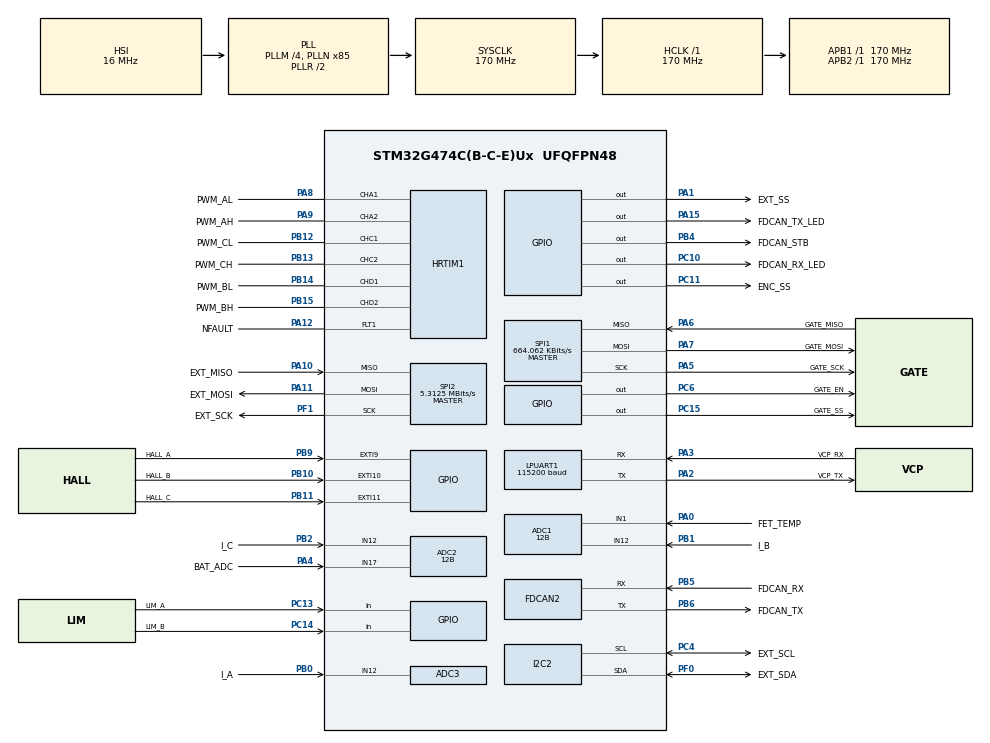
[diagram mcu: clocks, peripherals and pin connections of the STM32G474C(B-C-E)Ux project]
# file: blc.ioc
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ADC1.Channel-2\#ChannelRegularConversion=ADC_CHANNEL_1
ADC1.Channel-3\#ChannelRegularConversion=ADC_CHANNEL_TEMPSENSOR_ADC1
ADC1.Channel-4\#ChannelRegularConversion=ADC_CHANNEL_VREFINT
ADC1.ClockPrescaler=ADC_CLOCK_SYNC_PCLK_DIV4
ADC1.ContinuousConvMode=ENABLE
ADC1.DMAContinuousRequests=ENABLE
ADC1.DataAlign=ADC_DATAALIGN_RIGHT
ADC1.EnableInjectedConversion=ENABLE
ADC1.EnableRegularConversion=ENABLE
ADC1.ExternalTrigConv=ADC_SOFTWARE_START
ADC1.ExternalTrigInjecConv=ADC_EXTERNALTRIGINJEC_HRTIM_TRG5
ADC1.InjNumberOfConversion=1
ADC1.InjectedChannel-1\#ChannelInjectedConversion=ADC_CHANNEL_12
ADC1.InjectedOffset-1\#ChannelInjectedConversion=0
ADC1.InjectedOffsetNumber-1\#ChannelInjectedConversion=ADC_OFFSET_1
ADC1.InjectedOffsetSaturation-1\#ChannelInjectedConversion=DISABLE
ADC1.InjectedOffsetSign-1\#ChannelInjectedConversion=ADC_OFFSET_SIGN_NEGATIVE
ADC1.InjectedRank-1\#ChannelInjectedConversion=1
ADC1.InjectedSamplingTime-1\#ChannelInjectedConversion=ADC_SAMPLETIME_24CYCLES_5
ADC1.NbrOfConversion=3
ADC1.NbrOfConversionFlag=1
ADC1.OffsetNumber-2\#ChannelRegularConversion=ADC_OFFSET_NONE
ADC1.OffsetNumber-3\#ChannelRegularConversion=ADC_OFFSET_NONE
ADC1.OffsetNumber-4\#ChannelRegularConversion=ADC_OFFSET_NONE
ADC1.Overrun=ADC_OVR_DATA_OVERWRITTEN
ADC1.OversamplingMode=ENABLE
ADC1.OversamplingStopReset=ADC_REGOVERSAMPLING_CONTINUED_MODE
ADC1.Rank-2\#ChannelRegularConversion=1
ADC1.Rank-3\#ChannelRegularConversion=2
ADC1.Rank-4\#ChannelRegularConversion=3
ADC1.Ratio=ADC_OVERSAMPLING_RATIO_256
ADC1.Resolution=ADC_RESOLUTION_12B
ADC1.RightBitShift=ADC_RIGHTBITSHIFT_4
ADC1.SamplingTime-2\#ChannelRegularConversion=ADC_SAMPLETIME_47CYCLES_5
ADC1.SamplingTime-3\#ChannelRegularConversion=ADC_SAMPLETIME_247CYCLES_5
ADC1.SamplingTime-4\#ChannelRegularConversion=ADC_SAMPLETIME_247CYCLES_5
ADC1.ScanConvMode=ADC_SCAN_ENABLE
ADC1.TriggeredMode=ADC_TRIGGEREDMODE_SINGLE_TRIGGER
ADC1.master=1
ADC2.Channel-0\#ChannelRegularConversion=ADC_CHANNEL_17
ADC2.ClockPrescaler=ADC_CLOCK_SYNC_PCLK_DIV4
ADC2.ContinuousConvMode=ENABLE
ADC2.DMAContinuousRequests=ENABLE
ADC2.DataAlign=ADC_DATAALIGN_RIGHT
ADC2.EnableInjectedConversion=ENABLE
ADC2.EnableRegularConversion=ENABLE
ADC2.ExternalTrigConv=ADC_SOFTWARE_START
ADC2.ExternalTrigInjecConv=ADC_EXTERNALTRIGINJEC_HRTIM_TRG5
ADC2.InjNumberOfConversion=1
ADC2.InjectedChannel-1\#ChannelInjectedConversion=ADC_CHANNEL_12
ADC2.InjectedOffset-1\#ChannelInjectedConversion=0
ADC2.InjectedOffsetNumber-1\#ChannelInjectedConversion=ADC_OFFSET_1
ADC2.InjectedOffsetSaturation-1\#ChannelInjectedConversion=DISABLE
ADC2.InjectedOffsetSign-1\#ChannelInjectedConversion=ADC_OFFSET_SIGN_NEGATIVE
ADC2.InjectedRank-1\#ChannelInjectedConversion=1
ADC2.InjectedSamplingTime-1\#ChannelInjectedConversion=ADC_SAMPLETIME_24CYCLES_5
ADC2.NbrOfConversion=1
ADC2.NbrOfConversionFlag=1
ADC2.OffsetNumber-0\#ChannelRegularConversion=ADC_OFFSET_NONE
ADC2.Overrun=ADC_OVR_DATA_OVERWRITTEN
ADC2.OversamplingMode=ENABLE
ADC2.OversamplingStopReset=ADC_REGOVERSAMPLING_CONTINUED_MODE
ADC2.Rank-0\#ChannelRegularConversion=1
ADC2.Rank1_Channel=ADC_CHANNEL_12
ADC2.Ratio=ADC_OVERSAMPLING_RATIO_8
ADC2.Resolution=ADC_RESOLUTION_12B
ADC2.RightBitShift=ADC_RIGHTBITSHIFT_3
ADC2.SamplingTime-0\#ChannelRegularConversion=ADC_SAMPLETIME_247CYCLES_5
ADC2.TriggeredMode=ADC_TRIGGEREDMODE_SINGLE_TRIGGER
ADC3.ClockPrescaler=ADC_CLOCK_SYNC_PCLK_DIV4
ADC3.DataAlign=ADC_DATAALIGN_RIGHT
ADC3.EnableInjectedConversion=ENABLE
ADC3.EnableRegularConversion=DISABLE
ADC3.ExternalTrigInjecConv=ADC_EXTERNALTRIGINJEC_HRTIM_TRG5
ADC3.InjNumberOfConversion=1
ADC3.InjectedChannel-1\#ChannelInjectedConversion=ADC_CHANNEL_12
ADC3.InjectedOffset-1\#ChannelInjectedConversion=0
ADC3.InjectedOffsetNumber-1\#ChannelInjectedConversion=ADC_OFFSET_1
ADC3.InjectedOffsetSaturation-1\#ChannelInjectedConversion=DISABLE
ADC3.InjectedOffsetSign-1\#ChannelInjectedConversion=ADC_OFFSET_SIGN_NEGATIVE
ADC3.InjectedRank-1\#ChannelInjectedConversion=1
ADC3.InjectedSamplingTime-1\#ChannelInjectedConversion=ADC_SAMPLETIME_24CYCLES_5
ADC3.Rank1_Channel=ADC_CHANNEL_12
ADC3.Resolution=ADC_RESOLUTION_12B
ADC3.master=1
Dma.ADC1.0.Direction=DMA_PERIPH_TO_MEMORY
Dma.ADC1.0.EventEnable=DISABLE
Dma.ADC1.0.Instance=DMA1_Channel1
Dma.ADC1.0.MemDataAlignment=DMA_MDATAALIGN_HALFWORD
Dma.ADC1.0.MemInc=DMA_MINC_ENABLE
Dma.ADC1.0.Mode=DMA_CIRCULAR
Dma.ADC1.0.PeriphDataAlignment=DMA_PDATAALIGN_HALFWORD
Dma.ADC1.0.PeriphInc=DMA_PINC_DISABLE
Dma.ADC1.0.Polarity=HAL_DMAMUX_REQ_GEN_RISING
Dma.ADC1.0.Priority=DMA_PRIORITY_LOW
Dma.ADC1.0.RequestNumber=1
Dma.ADC1.0.SignalID=NONE
Dma.ADC1.0.SyncEnable=DISABLE
Dma.ADC1.0.SyncPolarity=HAL_DMAMUX_SYNC_NO_EVENT
Dma.ADC1.0.SyncRequestNumber=1
Dma.ADC1.0.SyncSignalID=NONE
Dma.ADC2.1.Direction=DMA_PERIPH_TO_MEMORY
Dma.ADC2.1.EventEnable=DISABLE
Dma.ADC2.1.Instance=DMA1_Channel2
Dma.ADC2.1.MemDataAlignment=DMA_MDATAALIGN_HALFWORD
Dma.ADC2.1.MemInc=DMA_MINC_ENABLE
Dma.ADC2.1.Mode=DMA_CIRCULAR
Dma.ADC2.1.PeriphDataAlignment=DMA_PDATAALIGN_HALFWORD
Dma.ADC2.1.PeriphInc=DMA_PINC_DISABLE
Dma.ADC2.1.Polarity=HAL_DMAMUX_REQ_GEN_RISING
Dma.ADC2.1.Priority=DMA_PRIORITY_LOW
Dma.ADC2.1.RequestNumber=1
Dma.ADC2.1.SignalID=NONE
Dma.ADC2.1.SyncEnable=DISABLE
Dma.ADC2.1.SyncPolarity=HAL_DMAMUX_SYNC_NO_EVENT
Dma.ADC2.1.SyncRequestNumber=1
Dma.ADC2.1.SyncSignalID=NONE
Dma.LPUART1_TX.4.Direction=DMA_MEMORY_TO_PERIPH
Dma.LPUART1_TX.4.EventEnable=DISABLE
Dma.LPUART1_TX.4.Instance=DMA1_Channel5
Dma.LPUART1_TX.4.MemDataAlignment=DMA_MDATAALIGN_BYTE
Dma.LPUART1_TX.4.MemInc=DMA_MINC_ENABLE
Dma.LPUART1_TX.4.Mode=DMA_NORMAL
Dma.LPUART1_TX.4.PeriphDataAlignment=DMA_PDATAALIGN_BYTE
Dma.LPUART1_TX.4.PeriphInc=DMA_PINC_DISABLE
Dma.LPUART1_TX.4.Polarity=HAL_DMAMUX_REQ_GEN_RISING
Dma.LPUART1_TX.4.Priority=DMA_PRIORITY_LOW
Dma.LPUART1_TX.4.RequestNumber=1
Dma.LPUART1_TX.4.SignalID=NONE
Dma.LPUART1_TX.4.SyncEnable=DISABLE
Dma.LPUART1_TX.4.SyncPolarity=HAL_DMAMUX_SYNC_NO_EVENT
Dma.LPUART1_TX.4.SyncRequestNumber=1
Dma.LPUART1_TX.4.SyncSignalID=NONE
Dma.Request0=ADC1
Dma.Request1=ADC2
Dma.Request2=SPI2_RX
Dma.Request3=SPI2_TX
Dma.Request4=LPUART1_TX
Dma.SPI2_RX.2.Direction=DMA_PERIPH_TO_MEMORY
Dma.SPI2_RX.2.EventEnable=DISABLE
Dma.SPI2_RX.2.Instance=DMA1_Channel3
Dma.SPI2_RX.2.MemDataAlignment=DMA_MDATAALIGN_HALFWORD
Dma.SPI2_RX.2.MemInc=DMA_MINC_ENABLE
Dma.SPI2_RX.2.Mode=DMA_NORMAL
Dma.SPI2_RX.2.PeriphDataAlignment=DMA_PDATAALIGN_HALFWORD
Dma.SPI2_RX.2.PeriphInc=DMA_PINC_DISABLE
Dma.SPI2_RX.2.Polarity=HAL_DMAMUX_REQ_GEN_RISING
Dma.SPI2_RX.2.Priority=DMA_PRIORITY_LOW
Dma.SPI2_RX.2.RequestNumber=1
Dma.SPI2_RX.2.SignalID=NONE
Dma.SPI2_RX.2.SyncEnable=DISABLE
Dma.SPI2_RX.2.SyncPolarity=HAL_DMAMUX_SYNC_NO_EVENT
Dma.SPI2_RX.2.SyncRequestNumber=1
Dma.SPI2_RX.2.SyncSignalID=NONE
Dma.SPI2_TX.3.Direction=DMA_MEMORY_TO_PERIPH
Dma.SPI2_TX.3.EventEnable=DISABLE
Dma.SPI2_TX.3.Instance=DMA1_Channel4
Dma.SPI2_TX.3.MemDataAlignment=DMA_MDATAALIGN_HALFWORD
Dma.SPI2_TX.3.MemInc=DMA_MINC_ENABLE
Dma.SPI2_TX.3.Mode=DMA_NORMAL
Dma.SPI2_TX.3.PeriphDataAlignment=DMA_PDATAALIGN_HALFWORD
Dma.SPI2_TX.3.PeriphInc=DMA_PINC_DISABLE
Dma.SPI2_TX.3.Polarity=HAL_DMAMUX_REQ_GEN_RISING
Dma.SPI2_TX.3.Priority=DMA_PRIORITY_LOW
Dma.SPI2_TX.3.RequestNumber=1
Dma.SPI2_TX.3.SignalID=NONE
Dma.SPI2_TX.3.SyncEnable=DISABLE
Dma.SPI2_TX.3.SyncPolarity=HAL_DMAMUX_SYNC_NO_EVENT
Dma.SPI2_TX.3.SyncRequestNumber=1
Dma.SPI2_TX.3.SyncSignalID=NONE
FDCAN2.AutoRetransmission=ENABLE
FDCAN2.CalculateBaudRateNominal=999999
FDCAN2.CalculateTimeBitNominal=1000
FDCAN2.CalculateTimeQuantumNominal=11.764705882352942
FDCAN2.DataPrescaler=2
FDCAN2.DataSyncJumpWidth=5
FDCAN2.DataTimeSeg1=11
FDCAN2.DataTimeSeg2=5
FDCAN2.ExtFiltersNbr=3
FDCAN2.FrameFormat=FDCAN_FRAME_FD_BRS
FDCAN2.NominalPrescaler=2
FDCAN2.NominalSyncJumpWidth=16
FDCAN2.NominalTimeSeg1=56
FDCAN2.NominalTimeSeg2=28
HRTIM1.ADCTrigger_Id5=HRTIM_ADCTRIGGER_5
HRTIM1.Adrom_TA=HRTIM_TIM_ADROM_VALLEY
HRTIM1.CalibrationRate_nonIT=HRTIM_CALIBRATIONRATE_0
HRTIM1.CompareUnit1-Output_TA1TA2=HRTIM_COMPAREUNIT_1
HRTIM1.CompareUnit1-Output_TC1TC2=HRTIM_COMPAREUNIT_1
HRTIM1.CompareUnit1-Output_TD1TD2=HRTIM_COMPAREUNIT_1
HRTIM1.CompareValue1-Output_TA1TA2=0x84A0
HRTIM1.CompareValue1-Output_TC1TC2=0x84A0
HRTIM1.CompareValue1-Output_TD1TD2=0x84A0
HRTIM1.DeadTimeInsertion-Output_TA1TA2=HRTIM_TIMDEADTIMEINSERTION_ENABLED
HRTIM1.DeadTimeInsertion-Output_TC1TC2=HRTIM_TIMDEADTIMEINSERTION_ENABLED
HRTIM1.DeadTimeInsertion-Output_TD1TD2=HRTIM_TIMDEADTIMEINSERTION_ENABLED
HRTIM1.Deadtimeconfig-Output_TA1TA2=HRTIM_TIMERINDEX_TIMER_A
HRTIM1.Deadtimeconfig-Output_TC1TC2=HRTIM_TIMERINDEX_TIMER_C
HRTIM1.Deadtimeconfig-Output_TD1TD2=HRTIM_TIMERINDEX_TIMER_D
HRTIM1.FallingValue-Output_TA1TA2=204
HRTIM1.FallingValue-Output_TC1TC2=204
HRTIM1.FallingValue-Output_TD1TD2=204
HRTIM1.FaultEnable_Source1-Output_TA1TA2=HRTIM_TIMFAULTENABLE_FAULT1
HRTIM1.FaultEnable_Source1-Output_TC1TC2=HRTIM_TIMFAULTENABLE_FAULT1
HRTIM1.FaultEnable_Source1-Output_TD1TD2=HRTIM_TIMFAULTENABLE_FAULT1
HRTIM1.FaultLevel1-Output_TA1TA2=HRTIM_OUTPUTFAULTLEVEL_INACTIVE
HRTIM1.FaultLevel1-Output_TC1TC2=HRTIM_OUTPUTFAULTLEVEL_INACTIVE
HRTIM1.FaultLevel1-Output_TD1TD2=HRTIM_OUTPUTFAULTLEVEL_INACTIVE
HRTIM1.FaultLevel2-Output_TA1TA2=HRTIM_OUTPUTFAULTLEVEL_INACTIVE
HRTIM1.FaultLevel2-Output_TC1TC2=HRTIM_OUTPUTFAULTLEVEL_INACTIVE
HRTIM1.FaultLevel2-Output_TD1TD2=HRTIM_OUTPUTFAULTLEVEL_INACTIVE
HRTIM1.Filter_FaultLine1=HRTIM_FAULTFILTER_10
HRTIM1.NumberFaultEnable-Output_TA1TA2=1
HRTIM1.NumberFaultEnable-Output_TC1TC2=1
HRTIM1.NumberFaultEnable-Output_TD1TD2=1
HRTIM1.NumberSetSource1-Output_TA1TA2=1
HRTIM1.NumberSetSource1-Output_TC1TC2=1
HRTIM1.NumberSetSource1-Output_TD1TD2=1
HRTIM1.ORingUpdateSource_ADCTrigger5=HRTIM_ADCTRIGGERUPDATE_TIMER_A
HRTIM1.Periode_TA=0x84D0
HRTIM1.Periode_TC=0x84D0
HRTIM1.Periode_TD=0x84D0
HRTIM1.Polarity_FaultLine1=HRTIM_FAULTPOLARITY_LOW
HRTIM1.PreloadEnable-Output_TA1TA2=HRTIM_PRELOAD_ENABLED
HRTIM1.PreloadEnable-Output_TC1TC2=HRTIM_PRELOAD_ENABLED
HRTIM1.PreloadEnable-Output_TD1TD2=HRTIM_PRELOAD_ENABLED
HRTIM1.PrescalerRatio_TA=HRTIM_PRESCALERRATIO_MUL8
HRTIM1.PrescalerRatio_TC=HRTIM_PRESCALERRATIO_MUL8
HRTIM1.PrescalerRatio_TD=HRTIM_PRESCALERRATIO_MUL8
HRTIM1.RepetitionUpdate-Output_TA1TA2=HRTIM_UPDATEONREPETITION_ENABLED
HRTIM1.RepetitionUpdate-Output_TC1TC2=HRTIM_UPDATEONREPETITION_ENABLED
HRTIM1.RepetitionUpdate-Output_TD1TD2=HRTIM_UPDATEONREPETITION_ENABLED
HRTIM1.RisingValue-Output_TA1TA2=204
HRTIM1.RisingValue-Output_TC1TC2=204
HRTIM1.RisingValue-Output_TD1TD2=204
HRTIM1.SetOutput1_Source1-Output_TA1TA2=HRTIM_OUTPUTSET_TIMCMP1
HRTIM1.SetOutput1_Source1-Output_TC1TC2=HRTIM_OUTPUTSET_TIMCMP1
HRTIM1.SetOutput1_Source1-Output_TD1TD2=HRTIM_OUTPUTSET_TIMCMP1
HRTIM1.Source_ADCTrigger5=HRTIM_ADCTRIGGEREVENT579_TIMERA_RESET
HRTIM1.Timeout=10
HRTIM1.UpDownMode-Output_TA1TA2=HRTIM_TIMERUPDOWNMODE_UPDOWN
HRTIM1.UpDownMode-Output_TC1TC2=HRTIM_TIMERUPDOWNMODE_UPDOWN
HRTIM1.UpDownMode-Output_TD1TD2=HRTIM_TIMERUPDOWNMODE_UPDOWN
I2C2.Timing=0x40B285C2
IWDG.Prescaler=IWDG_PRESCALER_32
IWDG.Reload=99
IWDG.Window=4095
LPUART1.BaudRate=115200
Mcu.Family=STM32G4
Mcu.Name=STM32G474C(B-C-E)Ux
Mcu.Package=UFQFPN48
NVIC.ADC1_2_IRQn=true\:1\:0\:false\:false\:true\:true\:true\:true
NVIC.DMA1_Channel1_IRQn=true\:6\:0\:false\:false\:true\:false\:true\:true
NVIC.DMA1_Channel2_IRQn=true\:6\:0\:false\:false\:true\:false\:true\:true
NVIC.DMA1_Channel3_IRQn=true\:3\:0\:false\:false\:true\:false\:true\:true
NVIC.DMA1_Channel4_IRQn=true\:3\:0\:false\:false\:true\:false\:true\:true
NVIC.DMA1_Channel5_IRQn=true\:5\:0\:false\:false\:true\:false\:true\:true
NVIC.EXTI15_10_IRQn=true\:2\:0\:false\:false\:true\:true\:true\:true
NVIC.EXTI9_5_IRQn=true\:2\:0\:false\:false\:true\:true\:true\:true
NVIC.FDCAN2_IT0_IRQn=true\:4\:0\:false\:false\:true\:true\:true\:true
NVIC.FDCAN2_IT1_IRQn=true\:4\:0\:false\:false\:true\:true\:true\:true
NVIC.HRTIM1_FLT_IRQn=true\:0\:0\:false\:false\:true\:true\:true\:true
NVIC.LPUART1_IRQn=true\:5\:0\:false\:false\:true\:true\:true\:true
NVIC.PriorityGroup=NVIC_PRIORITYGROUP_4
NVIC.SPI2_IRQn=true\:3\:0\:false\:false\:true\:true\:true\:true
PA0.GPIO_Label=FET_TEMP
PA0.Mode=IN1-Single-Ended
PA0.Signal=ADC1_IN1
PA1.GPIO_Label=EXT_SS
PA1.PinState=GPIO_PIN_SET
PA1.Signal=GPIO_Output
PA10.GPIO_Label=EXT_MISO
PA10.Mode=Full_Duplex_Master
PA10.Signal=SPI2_MISO
PA11.GPIO_Label=EXT_MOSI
PA11.Mode=Full_Duplex_Master
PA11.Signal=SPI2_MOSI
PA12.GPIO_Label=NFAULT
PA12.Mode=Fault_Enable1
PA12.Signal=HRTIM1_FLT1
PA13.GPIO_Label=SWDIO
PA13.Mode=Trace_Asynchronous_SW
PA13.Signal=SYS_JTMS-SWDIO
PA14.GPIO_Label=SWCLK
PA14.Mode=Trace_Asynchronous_SW
PA14.Signal=SYS_JTCK-SWCLK
PA15.GPIO_Label=FDCAN_TX_LED
PA15.Signal=GPIO_Output
PA2.GPIO_Label=VCP_TX
PA2.Mode=Asynchronous
PA2.Signal=LPUART1_TX
PA3.GPIO_Label=VCP_RX
PA3.Mode=Asynchronous
PA3.Signal=LPUART1_RX
PA4.GPIO_Label=BAT_ADC
PA4.Mode=IN17-Single-Ended
PA4.Signal=ADC2_IN17
PA5.GPIO_Label=GATE_SCK
PA5.Mode=Full_Duplex_Master
PA5.Signal=SPI1_SCK
PA6.GPIO_Label=GATE_MISO
PA6.Mode=Full_Duplex_Master
PA6.Signal=SPI1_MISO
PA7.GPIO_Label=GATE_MOSI
PA7.Mode=Full_Duplex_Master
PA7.Signal=SPI1_MOSI
PA8.GPIO_Label=PWM_AL
PA8.Mode=Output_TA1TA2
PA8.Signal=HRTIM1_CHA1
PA9.GPIO_Label=PWM_AH
PA9.Mode=Output_TA1TA2
PA9.Signal=HRTIM1_CHA2
PB0.GPIO_Label=I_A
PB0.Mode=IN12-Single-Ended
PB0.Signal=ADC3_IN12
PB1.GPIO_Label=I_B
PB1.Mode=IN12-Single-Ended
PB1.Signal=ADC1_IN12
PB10.GPIO_Label=HALL_B
PB10.GPIO_ModeDefaultEXTI=GPIO_MODE_IT_RISING_FALLING
PB10.Signal=GPXTI10
PB11.GPIO_Label=HALL_C
PB11.GPIO_ModeDefaultEXTI=GPIO_MODE_IT_RISING_FALLING
PB11.Signal=GPXTI11
PB12.GPIO_Label=PWM_CL
PB12.Mode=Output_TC1TC2
PB12.Signal=HRTIM1_CHC1
PB13.GPIO_Label=PWM_CH
PB13.Mode=Output_TC1TC2
PB13.Signal=HRTIM1_CHC2
PB14.GPIO_Label=PWM_BL
PB14.Mode=Output_TD1TD2
PB14.Signal=HRTIM1_CHD1
PB15.GPIO_Label=PWM_BH
PB15.Mode=Output_TD1TD2
PB15.Signal=HRTIM1_CHD2
PB2.GPIO_Label=I_C
PB2.Mode=IN12-Single-Ended
PB2.Signal=ADC2_IN12
PB3.GPIO_Label=SWO
PB3.Mode=Trace_Asynchronous_SW
PB3.Signal=SYS_JTDO-SWO
PB4.GPIO_Label=FDCAN_STB
PB4.Signal=GPIO_Output
PB5.GPIO_Label=FDCAN_RX
PB5.Mode=FDCAN_Activate
PB5.Signal=FDCAN2_RX
PB6.GPIO_Label=FDCAN_TX
PB6.Mode=FDCAN_Activate
PB6.Signal=FDCAN2_TX
PB9.GPIO_Label=HALL_A
PB9.GPIO_ModeDefaultEXTI=GPIO_MODE_IT_RISING_FALLING
PB9.Signal=GPXTI9
PC10.GPIO_Label=FDCAN_RX_LED
PC10.Signal=GPIO_Output
PC11.GPIO_Label=ENC_SS
PC11.PinState=GPIO_PIN_SET
PC11.Signal=GPIO_Output
PC13.GPIO_Label=LIM_A
PC13.GPIO_PuPd=GPIO_PULLUP
PC13.Signal=GPIO_Input
PC14-OSC32_IN.GPIO_Label=LIM_B
PC14-OSC32_IN.GPIO_PuPd=GPIO_PULLUP
PC14-OSC32_IN.Signal=GPIO_Input
PC15-OSC32_OUT.GPIO_Label=GATE_SS
PC15-OSC32_OUT.PinState=GPIO_PIN_SET
PC15-OSC32_OUT.Signal=GPIO_Output
PC4.GPIO_Label=EXT_SCL
PC4.Mode=I2C
PC4.Signal=I2C2_SCL
PC6.GPIO_Label=GATE_EN
PC6.Signal=GPIO_Output
PF0-OSC_IN.GPIO_Label=EXT_SDA
PF0-OSC_IN.Mode=I2C
PF0-OSC_IN.Signal=I2C2_SDA
PF1-OSC_OUT.GPIO_Label=EXT_SCK
PF1-OSC_OUT.Mode=Full_Duplex_Master
PF1-OSC_OUT.Signal=SPI2_SCK
ProjectManager.HeapSize=0x200
ProjectManager.StackSize=0x400
ProjectManager.TargetToolchain=CMake
RCC.ADC12Freq_Value=170000000
RCC.ADC345Freq_Value=170000000
RCC.AHBFreq_Value=170000000
RCC.APB1Freq_Value=170000000
RCC.APB1TimFreq_Value=170000000
RCC.APB2Freq_Value=170000000
RCC.APB2TimFreq_Value=170000000
RCC.CortexFreq_Value=170000000
RCC.EXTERNAL_CLOCK_VALUE=12288000
RCC.HCLKFreq_Value=170000000
RCC.HSE_VALUE=8000000
RCC.HSI48_VALUE=48000000
RCC.HSI_VALUE=16000000
RCC.LSE_VALUE=32768
RCC.PLLM=RCC_PLLM_DIV4
RCC.PLLN=85
RCC.SYSCLKFreq_VALUE=170000000
RCC.SYSCLKSource=RCC_SYSCLKSOURCE_PLLCLK
RCC.USBFreq_Value=170000000
RCC.VCOOutputFreq_Value=340000000
SPI1.BaudRatePrescaler=SPI_BAUDRATEPRESCALER_256
SPI1.CLKPhase=SPI_PHASE_2EDGE
SPI1.CLKPolarity=SPI_POLARITY_LOW
SPI1.CRCCalculation=SPI_CRCCALCULATION_DISABLE
SPI1.CalculateBaudRate=664.062 KBits/s
SPI1.DataSize=SPI_DATASIZE_16BIT
SPI1.Direction=SPI_DIRECTION_2LINES
SPI1.FirstBit=SPI_FIRSTBIT_MSB
SPI1.Mode=SPI_MODE_MASTER
SPI1.VirtualType=VM_MASTER
SPI2.BaudRatePrescaler=SPI_BAUDRATEPRESCALER_32
SPI2.CLKPhase=SPI_PHASE_2EDGE
SPI2.CLKPolarity=SPI_POLARITY_LOW
SPI2.CRCCalculation=SPI_CRCCALCULATION_DISABLE
SPI2.CalculateBaudRate=5.3125 MBits/s
SPI2.DataSize=SPI_DATASIZE_16BIT
SPI2.Direction=SPI_DIRECTION_2LINES
SPI2.FirstBit=SPI_FIRSTBIT_MSB
SPI2.Mode=SPI_MODE_MASTER
SPI2.VirtualType=VM_MASTER
TIM2.AutoReloadPreload=TIM_AUTORELOAD_PRELOAD_DISABLE
TIM2.ClockDivision=TIM_CLOCKDIVISION_DIV1
TIM2.CounterMode=TIM_COUNTERMODE_UP
TIM2.PeriodNoDither=4294967295
TIM2.Prescaler=0
VP_ADC1_TempSens_Input.Mode=IN-TempSens
VP_ADC1_Vref_Input.Mode=IN-Vrefint
VP_CORDIC_VS_CORDIC.Mode=CORDIC_Activate
VP_FMAC_VS_FMAC.Mode=FMAC_Activate
VP_IWDG_VS_IWDG.Mode=IWDG_Activate
VP_SYS_VS_DBSignals.Mode=DisableDeadBatterySignals
VP_TIM2_VS_ClockSourceINT.Mode=Internal
board=custom

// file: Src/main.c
/* USER CODE BEGIN Header */
/**
  ******************************************************************************
  * @file           : main.c
  * @brief          : Main program body
  ******************************************************************************
  * @attention
  *
  * Copyright (c) 2026 STMicroelectronics.
  * All rights reserved.
  *
  * This software is licensed under terms that can be found in the LICENSE file
  * in the root directory of this software component.
  * If no LICENSE file comes with this software, it is provided AS-IS.
  *
  ******************************************************************************
  */
/* USER CODE END Header */
#include "main.h"

ADC_HandleTypeDef hadc1;
ADC_HandleTypeDef hadc2;
ADC_HandleTypeDef hadc3;
DMA_HandleTypeDef hdma_adc1;
DMA_HandleTypeDef hdma_adc2;

CORDIC_HandleTypeDef hcordic;

FDCAN_HandleTypeDef hfdcan2;

FMAC_HandleTypeDef hfmac;

HRTIM_HandleTypeDef hhrtim1;

I2C_HandleTypeDef hi2c2;

IWDG_HandleTypeDef hiwdg;

UART_HandleTypeDef hlpuart1;
DMA_HandleTypeDef hdma_lpuart1_tx;

SPI_HandleTypeDef hspi1;
SPI_HandleTypeDef hspi2;
DMA_HandleTypeDef hdma_spi2_rx;
DMA_HandleTypeDef hdma_spi2_tx;

TIM_HandleTypeDef htim2;

void SystemClock_Config(void);
static void MX_GPIO_Init(void);
static void MX_DMA_Init(void);
static void MX_ADC1_Init(void);
static void MX_ADC2_Init(void);
static void MX_ADC3_Init(void);
static void MX_FDCAN2_Init(void);
static void MX_HRTIM1_Init(void);
static void MX_I2C2_Init(void);
static void MX_LPUART1_UART_Init(void);
static void MX_SPI1_Init(void);
static void MX_SPI2_Init(void);
static void MX_TIM2_Init(void);
static void MX_CORDIC_Init(void);
static void MX_FMAC_Init(void);

int main(void)
{

  /* MCU Configuration--------------------------------------------------------*/

  /* Reset of all peripherals, Initializes the Flash interface and the Systick. */
  HAL_Init();

  /* Configure the system clock */
  SystemClock_Config();

  /* Initialize all configured peripherals */
  MX_GPIO_Init();
  MX_DMA_Init();
  MX_ADC1_Init();
  MX_ADC2_Init();
  MX_ADC3_Init();
  MX_FDCAN2_Init();
  MX_HRTIM1_Init();
  MX_I2C2_Init();
  MX_LPUART1_UART_Init();
  MX_SPI1_Init();
  MX_SPI2_Init();
  MX_TIM2_Init();
  MX_CORDIC_Init();
  MX_FMAC_Init();

  /* Infinite loop */
  while (1)
  {

  }
}

void SystemClock_Config(void)
{
  RCC_OscInitTypeDef RCC_OscInitStruct = {0};
  RCC_ClkInitTypeDef RCC_ClkInitStruct = {0};

  /** Configure the main internal regulator output voltage
  */
  HAL_PWREx_ControlVoltageScaling(PWR_REGULATOR_VOLTAGE_SCALE1_BOOST);

  /** Initializes the RCC Oscillators according to the specified parameters
  * in the RCC_OscInitTypeDef structure.
  */
  RCC_OscInitStruct.OscillatorType = RCC_OSCILLATORTYPE_HSI|RCC_OSCILLATORTYPE_LSI;
  RCC_OscInitStruct.HSIState = RCC_HSI_ON;
  RCC_OscInitStruct.HSICalibrationValue = RCC_HSICALIBRATION_DEFAULT;
  RCC_OscInitStruct.LSIState = RCC_LSI_ON;
  RCC_OscInitStruct.PLL.PLLState = RCC_PLL_ON;
  RCC_OscInitStruct.PLL.PLLSource = RCC_PLLSOURCE_HSI;
  RCC_OscInitStruct.PLL.PLLM = RCC_PLLM_DIV4;
  RCC_OscInitStruct.PLL.PLLN = 85;
  RCC_OscInitStruct.PLL.PLLP = RCC_PLLP_DIV2;
  RCC_OscInitStruct.PLL.PLLQ = RCC_PLLQ_DIV2;
  RCC_OscInitStruct.PLL.PLLR = RCC_PLLR_DIV2;
  if (HAL_RCC_OscConfig(&RCC_OscInitStruct) != HAL_OK)
  {
    Error_Handler();
  }

  /** Initializes the CPU, AHB and APB buses clocks
  */
  RCC_ClkInitStruct.ClockType = RCC_CLOCKTYPE_HCLK|RCC_CLOCKTYPE_SYSCLK
                              |RCC_CLOCKTYPE_PCLK1|RCC_CLOCKTYPE_PCLK2;
  RCC_ClkInitStruct.SYSCLKSource = RCC_SYSCLKSOURCE_PLLCLK;
  RCC_ClkInitStruct.AHBCLKDivider = RCC_SYSCLK_DIV1;
  RCC_ClkInitStruct.APB1CLKDivider = RCC_HCLK_DIV1;
  RCC_ClkInitStruct.APB2CLKDivider = RCC_HCLK_DIV1;

  if (HAL_RCC_ClockConfig(&RCC_ClkInitStruct, FLASH_LATENCY_4) != HAL_OK)
  {
    Error_Handler();
  }
}

static void MX_ADC1_Init(void)
{

  ADC_MultiModeTypeDef multimode = {0};
  ADC_InjectionConfTypeDef sConfigInjected = {0};
  ADC_ChannelConfTypeDef sConfig = {0};

  /** Common config
  */
  hadc1.Instance = ADC1;
  hadc1.Init.ClockPrescaler = ADC_CLOCK_SYNC_PCLK_DIV4;
  hadc1.Init.Resolution = ADC_RESOLUTION_12B;
  hadc1.Init.DataAlign = ADC_DATAALIGN_RIGHT;
  hadc1.Init.GainCompensation = 0;
  hadc1.Init.ScanConvMode = ADC_SCAN_ENABLE;
  hadc1.Init.EOCSelection = ADC_EOC_SINGLE_CONV;
  hadc1.Init.LowPowerAutoWait = DISABLE;
  hadc1.Init.ContinuousConvMode = ENABLE;
  hadc1.Init.NbrOfConversion = 3;
  hadc1.Init.DiscontinuousConvMode = DISABLE;
  hadc1.Init.ExternalTrigConv = ADC_SOFTWARE_START;
  hadc1.Init.ExternalTrigConvEdge = ADC_EXTERNALTRIGCONVEDGE_NONE;
  hadc1.Init.DMAContinuousRequests = ENABLE;
  hadc1.Init.Overrun = ADC_OVR_DATA_OVERWRITTEN;
  hadc1.Init.OversamplingMode = ENABLE;
  hadc1.Init.Oversampling.Ratio = ADC_OVERSAMPLING_RATIO_256;
  hadc1.Init.Oversampling.RightBitShift = ADC_RIGHTBITSHIFT_4;
  hadc1.Init.Oversampling.TriggeredMode = ADC_TRIGGEREDMODE_SINGLE_TRIGGER;
  hadc1.Init.Oversampling.OversamplingStopReset = ADC_REGOVERSAMPLING_CONTINUED_MODE;
  if (HAL_ADC_Init(&hadc1) != HAL_OK)
  {
    Error_Handler();
  }

  /** Configure the ADC multi-mode
  */
  multimode.Mode = ADC_MODE_INDEPENDENT;
  if (HAL_ADCEx_MultiModeConfigChannel(&hadc1, &multimode) != HAL_OK)
  {
    Error_Handler();
  }

  /** Configure Injected Channel
  */
  sConfigInjected.InjectedChannel = ADC_CHANNEL_12;
  sConfigInjected.InjectedRank = ADC_INJECTED_RANK_1;
  sConfigInjected.InjectedSamplingTime = ADC_SAMPLETIME_24CYCLES_5;
  sConfigInjected.InjectedSingleDiff = ADC_SINGLE_ENDED;
  sConfigInjected.InjectedOffsetNumber = ADC_OFFSET_1;
  sConfigInjected.InjectedOffset = 0;
  sConfigInjected.InjectedOffsetSign = ADC_OFFSET_SIGN_NEGATIVE;
  sConfigInjected.InjectedOffsetSaturation = DISABLE;
  sConfigInjected.InjectedNbrOfConversion = 1;
  sConfigInjected.InjectedDiscontinuousConvMode = DISABLE;
  sConfigInjected.AutoInjectedConv = DISABLE;
  sConfigInjected.QueueInjectedContext = DISABLE;
  sConfigInjected.ExternalTrigInjecConv = ADC_EXTERNALTRIGINJEC_HRTIM_TRG5;
  sConfigInjected.ExternalTrigInjecConvEdge = ADC_EXTERNALTRIGINJECCONV_EDGE_RISING;
  sConfigInjected.InjecOversamplingMode = DISABLE;
  if (HAL_ADCEx_InjectedConfigChannel(&hadc1, &sConfigInjected) != HAL_OK)
  {
    Error_Handler();
  }

  /** Configure Regular Channel
  */
  sConfig.Channel = ADC_CHANNEL_1;
  sConfig.Rank = ADC_REGULAR_RANK_1;
  sConfig.SamplingTime = ADC_SAMPLETIME_47CYCLES_5;
  sConfig.SingleDiff = ADC_SINGLE_ENDED;
  sConfig.OffsetNumber = ADC_OFFSET_NONE;
  sConfig.Offset = 0;
  if (HAL_ADC_ConfigChannel(&hadc1, &sConfig) != HAL_OK)
  {
    Error_Handler();
  }

  /** Configure Regular Channel
  */
  sConfig.Channel = ADC_CHANNEL_TEMPSENSOR_ADC1;
  sConfig.Rank = ADC_REGULAR_RANK_2;
  sConfig.SamplingTime = ADC_SAMPLETIME_247CYCLES_5;
  if (HAL_ADC_ConfigChannel(&hadc1, &sConfig) != HAL_OK)
  {
    Error_Handler();
  }

  /** Configure Regular Channel
  */
  sConfig.Channel = ADC_CHANNEL_VREFINT;
  sConfig.Rank = ADC_REGULAR_RANK_3;
  if (HAL_ADC_ConfigChannel(&hadc1, &sConfig) != HAL_OK)
  {
    Error_Handler();
  }

}

static void MX_ADC2_Init(void)
{

  ADC_ChannelConfTypeDef sConfig = {0};
  ADC_InjectionConfTypeDef sConfigInjected = {0};

  /** Common config
  */
  hadc2.Instance = ADC2;
  hadc2.Init.ClockPrescaler = ADC_CLOCK_SYNC_PCLK_DIV4;
  hadc2.Init.Resolution = ADC_RESOLUTION_12B;
  hadc2.Init.DataAlign = ADC_DATAALIGN_RIGHT;
  hadc2.Init.GainCompensation = 0;
  hadc2.Init.ScanConvMode = ADC_SCAN_DISABLE;
  hadc2.Init.EOCSelection = ADC_EOC_SINGLE_CONV;
  hadc2.Init.LowPowerAutoWait = DISABLE;
  hadc2.Init.ContinuousConvMode = ENABLE;
  hadc2.Init.NbrOfConversion = 1;
  hadc2.Init.DiscontinuousConvMode = DISABLE;
  hadc2.Init.ExternalTrigConv = ADC_SOFTWARE_START;
  hadc2.Init.ExternalTrigConvEdge = ADC_EXTERNALTRIGCONVEDGE_NONE;
  hadc2.Init.DMAContinuousRequests = ENABLE;
  hadc2.Init.Overrun = ADC_OVR_DATA_OVERWRITTEN;
  hadc2.Init.OversamplingMode = ENABLE;
  hadc2.Init.Oversampling.Ratio = ADC_OVERSAMPLING_RATIO_8;
  hadc2.Init.Oversampling.RightBitShift = ADC_RIGHTBITSHIFT_3;
  hadc2.Init.Oversampling.TriggeredMode = ADC_TRIGGEREDMODE_SINGLE_TRIGGER;
  hadc2.Init.Oversampling.OversamplingStopReset = ADC_REGOVERSAMPLING_CONTINUED_MODE;
  if (HAL_ADC_Init(&hadc2) != HAL_OK)
  {
    Error_Handler();
  }

  /** Configure Regular Channel
  */
  sConfig.Channel = ADC_CHANNEL_17;
  sConfig.Rank = ADC_REGULAR_RANK_1;
  sConfig.SamplingTime = ADC_SAMPLETIME_247CYCLES_5;
  sConfig.SingleDiff = ADC_SINGLE_ENDED;
  sConfig.OffsetNumber = ADC_OFFSET_NONE;
  sConfig.Offset = 0;
  if (HAL_ADC_ConfigChannel(&hadc2, &sConfig) != HAL_OK)
  {
    Error_Handler();
  }

  /** Configure Injected Channel
  */
  sConfigInjected.InjectedChannel = ADC_CHANNEL_12;
  sConfigInjected.InjectedRank = ADC_INJECTED_RANK_1;
  sConfigInjected.InjectedSamplingTime = ADC_SAMPLETIME_24CYCLES_5;
  sConfigInjected.InjectedSingleDiff = ADC_SINGLE_ENDED;
  sConfigInjected.InjectedOffsetNumber = ADC_OFFSET_1;
  sConfigInjected.InjectedOffset = 0;
  sConfigInjected.InjectedOffsetSign = ADC_OFFSET_SIGN_NEGATIVE;
  sConfigInjected.InjectedOffsetSaturation = DISABLE;
  sConfigInjected.InjectedNbrOfConversion = 1;
  sConfigInjected.InjectedDiscontinuousConvMode = DISABLE;
  sConfigInjected.AutoInjectedConv = DISABLE;
  sConfigInjected.QueueInjectedContext = DISABLE;
  sConfigInjected.ExternalTrigInjecConv = ADC_EXTERNALTRIGINJEC_HRTIM_TRG5;
  sConfigInjected.ExternalTrigInjecConvEdge = ADC_EXTERNALTRIGINJECCONV_EDGE_RISING;
  sConfigInjected.InjecOversamplingMode = DISABLE;
  if (HAL_ADCEx_InjectedConfigChannel(&hadc2, &sConfigInjected) != HAL_OK)
  {
    Error_Handler();
  }

}

static void MX_ADC3_Init(void)
{

  ADC_MultiModeTypeDef multimode = {0};
  ADC_InjectionConfTypeDef sConfigInjected = {0};

  /** Common config
  */
  hadc3.Instance = ADC3;
  hadc3.Init.ClockPrescaler = ADC_CLOCK_SYNC_PCLK_DIV4;
  hadc3.Init.Resolution = ADC_RESOLUTION_12B;
  hadc3.Init.DataAlign = ADC_DATAALIGN_RIGHT;
  hadc3.Init.GainCompensation = 0;
  hadc3.Init.ScanConvMode = ADC_SCAN_DISABLE;
  hadc3.Init.EOCSelection = ADC_EOC_SINGLE_CONV;
  hadc3.Init.LowPowerAutoWait = DISABLE;
  hadc3.Init.ContinuousConvMode = DISABLE;
  hadc3.Init.NbrOfConversion = 1;
  hadc3.Init.DiscontinuousConvMode = DISABLE;
  hadc3.Init.DMAContinuousRequests = DISABLE;
  hadc3.Init.Overrun = ADC_OVR_DATA_PRESERVED;
  hadc3.Init.OversamplingMode = DISABLE;
  if (HAL_ADC_Init(&hadc3) != HAL_OK)
  {
    Error_Handler();
  }

  /** Configure the ADC multi-mode
  */
  multimode.Mode = ADC_MODE_INDEPENDENT;
  if (HAL_ADCEx_MultiModeConfigChannel(&hadc3, &multimode) != HAL_OK)
  {
    Error_Handler();
  }

  /** Configure Injected Channel
  */
  sConfigInjected.InjectedChannel = ADC_CHANNEL_12;
  sConfigInjected.InjectedRank = ADC_INJECTED_RANK_1;
  sConfigInjected.InjectedSamplingTime = ADC_SAMPLETIME_24CYCLES_5;
  sConfigInjected.InjectedSingleDiff = ADC_SINGLE_ENDED;
  sConfigInjected.InjectedOffsetNumber = ADC_OFFSET_1;
  sConfigInjected.InjectedOffset = 0;
  sConfigInjected.InjectedOffsetSign = ADC_OFFSET_SIGN_NEGATIVE;
  sConfigInjected.InjectedOffsetSaturation = DISABLE;
  sConfigInjected.InjectedNbrOfConversion = 1;
  sConfigInjected.InjectedDiscontinuousConvMode = DISABLE;
  sConfigInjected.AutoInjectedConv = DISABLE;
  sConfigInjected.QueueInjectedContext = DISABLE;
  sConfigInjected.ExternalTrigInjecConv = ADC_EXTERNALTRIGINJEC_HRTIM_TRG5;
  sConfigInjected.ExternalTrigInjecConvEdge = ADC_EXTERNALTRIGINJECCONV_EDGE_RISING;
  sConfigInjected.InjecOversamplingMode = DISABLE;
  if (HAL_ADCEx_InjectedConfigChannel(&hadc3, &sConfigInjected) != HAL_OK)
  {
    Error_Handler();
  }

}

static void MX_CORDIC_Init(void)
{

  hcordic.Instance = CORDIC;
  if (HAL_CORDIC_Init(&hcordic) != HAL_OK)
  {
    Error_Handler();
  }

}

static void MX_FDCAN2_Init(void)
{

  hfdcan2.Instance = FDCAN2;
  hfdcan2.Init.ClockDivider = FDCAN_CLOCK_DIV1;
  hfdcan2.Init.FrameFormat = FDCAN_FRAME_FD_BRS;
  hfdcan2.Init.Mode = FDCAN_MODE_NORMAL;
  hfdcan2.Init.AutoRetransmission = ENABLE;
  hfdcan2.Init.TransmitPause = DISABLE;
  hfdcan2.Init.ProtocolException = DISABLE;
  hfdcan2.Init.NominalPrescaler = 2;
  hfdcan2.Init.NominalSyncJumpWidth = 16;
  hfdcan2.Init.NominalTimeSeg1 = 56;
  hfdcan2.Init.NominalTimeSeg2 = 28;
  hfdcan2.Init.DataPrescaler = 2;
  hfdcan2.Init.DataSyncJumpWidth = 5;
  hfdcan2.Init.DataTimeSeg1 = 11;
  hfdcan2.Init.DataTimeSeg2 = 5;
  hfdcan2.Init.StdFiltersNbr = 0;
  hfdcan2.Init.ExtFiltersNbr = 3;
  hfdcan2.Init.TxFifoQueueMode = FDCAN_TX_FIFO_OPERATION;
  if (HAL_FDCAN_Init(&hfdcan2) != HAL_OK)
  {
    Error_Handler();
  }

}

static void MX_FMAC_Init(void)
{

  hfmac.Instance = FMAC;
  if (HAL_FMAC_Init(&hfmac) != HAL_OK)
  {
    Error_Handler();
  }

}

static void MX_HRTIM1_Init(void)
{

  HRTIM_FaultCfgTypeDef pFaultCfg = {0};
  HRTIM_FaultBlankingCfgTypeDef pFaultBlkCfg = {0};
  HRTIM_ADCTriggerCfgTypeDef pADCTriggerCfg = {0};
  HRTIM_TimeBaseCfgTypeDef pTimeBaseCfg = {0};
  HRTIM_TimerCtlTypeDef pTimerCtl = {0};
  HRTIM_TimerCfgTypeDef pTimerCfg = {0};
  HRTIM_CompareCfgTypeDef pCompareCfg = {0};
  HRTIM_DeadTimeCfgTypeDef pDeadTimeCfg = {0};
  HRTIM_OutputCfgTypeDef pOutputCfg = {0};

  hhrtim1.Instance = HRTIM1;
  hhrtim1.Init.HRTIMInterruptResquests = HRTIM_IT_NONE;
  hhrtim1.Init.SyncOptions = HRTIM_SYNCOPTION_NONE;
  if (HAL_HRTIM_Init(&hhrtim1) != HAL_OK)
  {
    Error_Handler();
  }
  if (HAL_HRTIM_DLLCalibrationStart(&hhrtim1, HRTIM_CALIBRATIONRATE_0) != HAL_OK)
  {
    Error_Handler();
  }
  if (HAL_HRTIM_PollForDLLCalibration(&hhrtim1, 10) != HAL_OK)
  {
    Error_Handler();
  }
  if (HAL_HRTIM_FaultPrescalerConfig(&hhrtim1, HRTIM_FAULTPRESCALER_DIV1) != HAL_OK)
  {
    Error_Handler();
  }
  pFaultCfg.Source = HRTIM_FAULTSOURCE_DIGITALINPUT;
  pFaultCfg.Polarity = HRTIM_FAULTPOLARITY_LOW;
  pFaultCfg.Filter = HRTIM_FAULTFILTER_10;
  pFaultCfg.Lock = HRTIM_FAULTLOCK_READWRITE;
  if (HAL_HRTIM_FaultConfig(&hhrtim1, HRTIM_FAULT_1, &pFaultCfg) != HAL_OK)
  {
    Error_Handler();
  }
  pFaultBlkCfg.Threshold = 0;
  pFaultBlkCfg.ResetMode = HRTIM_FAULTCOUNTERRST_UNCONDITIONAL;
  pFaultBlkCfg.BlankingSource = HRTIM_FAULTBLANKINGMODE_RSTALIGNED;
  if (HAL_HRTIM_FaultCounterConfig(&hhrtim1, HRTIM_FAULT_1, &pFaultBlkCfg) != HAL_OK)
  {
    Error_Handler();
  }
  if (HAL_HRTIM_FaultBlankingConfigAndEnable(&hhrtim1, HRTIM_FAULT_1, &pFaultBlkCfg) != HAL_OK)
  {
    Error_Handler();
  }
  HAL_HRTIM_FaultModeCtl(&hhrtim1, HRTIM_FAULT_1, HRTIM_FAULTMODECTL_ENABLED);
  pADCTriggerCfg.UpdateSource = HRTIM_ADCTRIGGERUPDATE_TIMER_A;
  pADCTriggerCfg.Trigger = HRTIM_ADCTRIGGEREVENT579_TIMERA_RESET;
  if (HAL_HRTIM_ADCTriggerConfig(&hhrtim1, HRTIM_ADCTRIGGER_5, &pADCTriggerCfg) != HAL_OK)
  {
    Error_Handler();
  }
  if (HAL_HRTIM_ADCPostScalerConfig(&hhrtim1, HRTIM_ADCTRIGGER_5, 0x0) != HAL_OK)
  {
    Error_Handler();
  }
  pTimeBaseCfg.Period = 0x84D0;
  pTimeBaseCfg.RepetitionCounter = 0x00;
  pTimeBaseCfg.PrescalerRatio = HRTIM_PRESCALERRATIO_MUL8;
  pTimeBaseCfg.Mode = HRTIM_MODE_CONTINUOUS;
  if (HAL_HRTIM_TimeBaseConfig(&hhrtim1, HRTIM_TIMERINDEX_TIMER_A, &pTimeBaseCfg) != HAL_OK)
  {
    Error_Handler();
  }
  pTimerCtl.UpDownMode = HRTIM_TIMERUPDOWNMODE_UPDOWN;
  pTimerCtl.GreaterCMP1 = HRTIM_TIMERGTCMP1_EQUAL;
  pTimerCtl.DualChannelDacEnable = HRTIM_TIMER_DCDE_DISABLED;
  if (HAL_HRTIM_WaveformTimerControl(&hhrtim1, HRTIM_TIMERINDEX_TIMER_A, &pTimerCtl) != HAL_OK)
  {
    Error_Handler();
  }
  if (HAL_HRTIM_RollOverModeConfig(&hhrtim1, HRTIM_TIMERINDEX_TIMER_A, HRTIM_TIM_FEROM_BOTH|HRTIM_TIM_BMROM_BOTH
                              |HRTIM_TIM_ADROM_VALLEY|HRTIM_TIM_OUTROM_BOTH
                              |HRTIM_TIM_ROM_BOTH) != HAL_OK)
  {
    Error_Handler();
  }
  pTimerCfg.InterruptRequests = HRTIM_TIM_IT_NONE;
  pTimerCfg.DMARequests = HRTIM_TIM_DMA_NONE;
  pTimerCfg.DMASrcAddress = 0x0000;
  pTimerCfg.DMADstAddress = 0x0000;
  pTimerCfg.DMASize = 0x1;
  pTimerCfg.HalfModeEnable = HRTIM_HALFMODE_DISABLED;
  pTimerCfg.InterleavedMode = HRTIM_INTERLEAVED_MODE_DISABLED;
  pTimerCfg.StartOnSync = HRTIM_SYNCSTART_DISABLED;
  pTimerCfg.ResetOnSync = HRTIM_SYNCRESET_DISABLED;
  pTimerCfg.DACSynchro = HRTIM_DACSYNC_NONE;
  pTimerCfg.PreloadEnable = HRTIM_PRELOAD_ENABLED;
  pTimerCfg.UpdateGating = HRTIM_UPDATEGATING_INDEPENDENT;
  pTimerCfg.BurstMode = HRTIM_TIMERBURSTMODE_MAINTAINCLOCK;
  pTimerCfg.RepetitionUpdate = HRTIM_UPDATEONREPETITION_ENABLED;
  pTimerCfg.PushPull = HRTIM_TIMPUSHPULLMODE_DISABLED;
  pTimerCfg.FaultEnable = HRTIM_TIMFAULTENABLE_FAULT1;
  pTimerCfg.FaultLock = HRTIM_TIMFAULTLOCK_READWRITE;
  pTimerCfg.DeadTimeInsertion = HRTIM_TIMDEADTIMEINSERTION_ENABLED;
  pTimerCfg.DelayedProtectionMode = HRTIM_TIMER_A_B_C_DELAYEDPROTECTION_DISABLED;
  pTimerCfg.UpdateTrigger = HRTIM_TIMUPDATETRIGGER_NONE;
  pTimerCfg.ResetTrigger = HRTIM_TIMRESETTRIGGER_NONE;
  pTimerCfg.ResetUpdate = HRTIM_TIMUPDATEONRESET_DISABLED;
  pTimerCfg.ReSyncUpdate = HRTIM_TIMERESYNC_UPDATE_UNCONDITIONAL;
  if (HAL_HRTIM_WaveformTimerConfig(&hhrtim1, HRTIM_TIMERINDEX_TIMER_A, &pTimerCfg) != HAL_OK)
  {
    Error_Handler();
  }
  if (HAL_HRTIM_WaveformTimerConfig(&hhrtim1, HRTIM_TIMERINDEX_TIMER_C, &pTimerCfg) != HAL_OK)
  {
    Error_Handler();
  }
  pTimerCfg.DelayedProtectionMode = HRTIM_TIMER_D_E_DELAYEDPROTECTION_DISABLED;
  if (HAL_HRTIM_WaveformTimerConfig(&hhrtim1, HRTIM_TIMERINDEX_TIMER_D, &pTimerCfg) != HAL_OK)
  {
    Error_Handler();
  }
  pCompareCfg.CompareValue = 0x84A0;
  if (HAL_HRTIM_WaveformCompareConfig(&hhrtim1, HRTIM_TIMERINDEX_TIMER_A, HRTIM_COMPAREUNIT_1, &pCompareCfg) != HAL_OK)
  {
    Error_Handler();
  }
  pDeadTimeCfg.Prescaler = HRTIM_TIMDEADTIME_PRESCALERRATIO_MUL8;
  pDeadTimeCfg.RisingValue = 204;
  pDeadTimeCfg.RisingSign = HRTIM_TIMDEADTIME_RISINGSIGN_POSITIVE;
  pDeadTimeCfg.RisingLock = HRTIM_TIMDEADTIME_RISINGLOCK_WRITE;
  pDeadTimeCfg.RisingSignLock = HRTIM_TIMDEADTIME_RISINGSIGNLOCK_WRITE;
  pDeadTimeCfg.FallingValue = 204;
  pDeadTimeCfg.FallingSign = HRTIM_TIMDEADTIME_FALLINGSIGN_POSITIVE;
  pDeadTimeCfg.FallingLock = HRTIM_TIMDEADTIME_FALLINGLOCK_WRITE;
  pDeadTimeCfg.FallingSignLock = HRTIM_TIMDEADTIME_FALLINGSIGNLOCK_WRITE;
  if (HAL_HRTIM_DeadTimeConfig(&hhrtim1, HRTIM_TIMERINDEX_TIMER_A, &pDeadTimeCfg) != HAL_OK)
  {
    Error_Handler();
  }
  if (HAL_HRTIM_DeadTimeConfig(&hhrtim1, HRTIM_TIMERINDEX_TIMER_C, &pDeadTimeCfg) != HAL_OK)
  {
    Error_Handler();
  }
  if (HAL_HRTIM_DeadTimeConfig(&hhrtim1, HRTIM_TIMERINDEX_TIMER_D, &pDeadTimeCfg) != HAL_OK)
  {
    Error_Handler();
  }
  pOutputCfg.Polarity = HRTIM_OUTPUTPOLARITY_HIGH;
  pOutputCfg.SetSource = HRTIM_OUTPUTSET_TIMCMP1;
  pOutputCfg.ResetSource = HRTIM_OUTPUTRESET_NONE;
  pOutputCfg.IdleMode = HRTIM_OUTPUTIDLEMODE_NONE;
  pOutputCfg.IdleLevel = HRTIM_OUTPUTIDLELEVEL_INACTIVE;
  pOutputCfg.FaultLevel = HRTIM_OUTPUTFAULTLEVEL_INACTIVE;
  pOutputCfg.ChopperModeEnable = HRTIM_OUTPUTCHOPPERMODE_DISABLED;
  pOutputCfg.BurstModeEntryDelayed = HRTIM_OUTPUTBURSTMODEENTRY_REGULAR;
  if (HAL_HRTIM_WaveformOutputConfig(&hhrtim1, HRTIM_TIMERINDEX_TIMER_A, HRTIM_OUTPUT_TA1, &pOutputCfg) != HAL_OK)
  {
    Error_Handler();
  }
  if (HAL_HRTIM_WaveformOutputConfig(&hhrtim1, HRTIM_TIMERINDEX_TIMER_C, HRTIM_OUTPUT_TC1, &pOutputCfg) != HAL_OK)
  {
    Error_Handler();
  }
  if (HAL_HRTIM_WaveformOutputConfig(&hhrtim1, HRTIM_TIMERINDEX_TIMER_D, HRTIM_OUTPUT_TD1, &pOutputCfg) != HAL_OK)
  {
    Error_Handler();
  }
  pOutputCfg.SetSource = HRTIM_OUTPUTSET_NONE;
  if (HAL_HRTIM_WaveformOutputConfig(&hhrtim1, HRTIM_TIMERINDEX_TIMER_A, HRTIM_OUTPUT_TA2, &pOutputCfg) != HAL_OK)
  {
    Error_Handler();
  }
  if (HAL_HRTIM_WaveformOutputConfig(&hhrtim1, HRTIM_TIMERINDEX_TIMER_C, HRTIM_OUTPUT_TC2, &pOutputCfg) != HAL_OK)
  {
    Error_Handler();
  }
  if (HAL_HRTIM_WaveformOutputConfig(&hhrtim1, HRTIM_TIMERINDEX_TIMER_D, HRTIM_OUTPUT_TD2, &pOutputCfg) != HAL_OK)
  {
    Error_Handler();
  }
  if (HAL_HRTIM_TimeBaseConfig(&hhrtim1, HRTIM_TIMERINDEX_TIMER_C, &pTimeBaseCfg) != HAL_OK)
  {
    Error_Handler();
  }
  if (HAL_HRTIM_WaveformTimerControl(&hhrtim1, HRTIM_TIMERINDEX_TIMER_C, &pTimerCtl) != HAL_OK)
  {
    Error_Handler();
  }
  if (HAL_HRTIM_RollOverModeConfig(&hhrtim1, HRTIM_TIMERINDEX_TIMER_C, HRTIM_TIM_FEROM_BOTH|HRTIM_TIM_BMROM_BOTH
                              |HRTIM_TIM_ADROM_BOTH|HRTIM_TIM_OUTROM_BOTH
                              |HRTIM_TIM_ROM_BOTH) != HAL_OK)
  {
    Error_Handler();
  }
  if (HAL_HRTIM_WaveformCompareConfig(&hhrtim1, HRTIM_TIMERINDEX_TIMER_C, HRTIM_COMPAREUNIT_1, &pCompareCfg) != HAL_OK)
  {
    Error_Handler();
  }
  if (HAL_HRTIM_TimeBaseConfig(&hhrtim1, HRTIM_TIMERINDEX_TIMER_D, &pTimeBaseCfg) != HAL_OK)
  {
    Error_Handler();
  }
  if (HAL_HRTIM_WaveformTimerControl(&hhrtim1, HRTIM_TIMERINDEX_TIMER_D, &pTimerCtl) != HAL_OK)
  {
    Error_Handler();
  }
  if (HAL_HRTIM_RollOverModeConfig(&hhrtim1, HRTIM_TIMERINDEX_TIMER_D, HRTIM_TIM_FEROM_BOTH|HRTIM_TIM_BMROM_BOTH
                              |HRTIM_TIM_ADROM_BOTH|HRTIM_TIM_OUTROM_BOTH
                              |HRTIM_TIM_ROM_BOTH) != HAL_OK)
  {
    Error_Handler();
  }
  if (HAL_HRTIM_WaveformCompareConfig(&hhrtim1, HRTIM_TIMERINDEX_TIMER_D, HRTIM_COMPAREUNIT_1, &pCompareCfg) != HAL_OK)
  {
    Error_Handler();
  }
  /* USER CODE BEGIN HRTIM1_Init 2 */
  /* CubeMX always enables fault 1 blanking (window: timer A reset/roll-over -> timer A CMP3,
   * RM0440 Table 252) and offers no option to turn it off. nFAULT must never be blanked.
   * FLT1BLKE is writable only while FLT1E = 0 (RM0440 HRTIM_FLTINR3); outputs are not enabled yet. */
  HAL_HRTIM_FaultModeCtl(&hhrtim1, HRTIM_FAULT_1, HRTIM_FAULTMODECTL_DISABLED);
  CLEAR_BIT(hhrtim1.Instance->sCommonRegs.FLTINR3, HRTIM_FLTINR3_FLT1BLKE);
  HAL_HRTIM_FaultModeCtl(&hhrtim1, HRTIM_FAULT_1, HRTIM_FAULTMODECTL_ENABLED);
  /* USER CODE END HRTIM1_Init 2 */
  HAL_HRTIM_MspPostInit(&hhrtim1);

}

static void MX_I2C2_Init(void)
{

  hi2c2.Instance = I2C2;
  hi2c2.Init.Timing = 0x40B285C2;
  hi2c2.Init.OwnAddress1 = 0;
  hi2c2.Init.AddressingMode = I2C_ADDRESSINGMODE_7BIT;
  hi2c2.Init.DualAddressMode = I2C_DUALADDRESS_DISABLE;
  hi2c2.Init.OwnAddress2 = 0;
  hi2c2.Init.OwnAddress2Masks = I2C_OA2_NOMASK;
  hi2c2.Init.GeneralCallMode = I2C_GENERALCALL_DISABLE;
  hi2c2.Init.NoStretchMode = I2C_NOSTRETCH_DISABLE;
  if (HAL_I2C_Init(&hi2c2) != HAL_OK)
  {
    Error_Handler();
  }

  /** Configure Analogue filter
  */
  if (HAL_I2CEx_ConfigAnalogFilter(&hi2c2, I2C_ANALOGFILTER_ENABLE) != HAL_OK)
  {
    Error_Handler();
  }

  /** Configure Digital filter
  */
  if (HAL_I2CEx_ConfigDigitalFilter(&hi2c2, 0) != HAL_OK)
  {
    Error_Handler();
  }

}

void MX_IWDG_Init(void)
{

  hiwdg.Instance = IWDG;
  hiwdg.Init.Prescaler = IWDG_PRESCALER_32;
  hiwdg.Init.Window = 4095;
  hiwdg.Init.Reload = 99;
  if (HAL_IWDG_Init(&hiwdg) != HAL_OK)
  {
    Error_Handler();
  }

}

static void MX_LPUART1_UART_Init(void)
{

  hlpuart1.Instance = LPUART1;
  hlpuart1.Init.BaudRate = 115200;
  hlpuart1.Init.WordLength = UART_WORDLENGTH_8B;
  hlpuart1.Init.StopBits = UART_STOPBITS_1;
  hlpuart1.Init.Parity = UART_PARITY_NONE;
  hlpuart1.Init.Mode = UART_MODE_TX_RX;
  hlpuart1.Init.HwFlowCtl = UART_HWCONTROL_NONE;
  hlpuart1.Init.OneBitSampling = UART_ONE_BIT_SAMPLE_DISABLE;
  hlpuart1.Init.ClockPrescaler = UART_PRESCALER_DIV1;
  hlpuart1.AdvancedInit.AdvFeatureInit = UART_ADVFEATURE_NO_INIT;
  if (HAL_UART_Init(&hlpuart1) != HAL_OK)
  {
    Error_Handler();
  }
  if (HAL_UARTEx_SetTxFifoThreshold(&hlpuart1, UART_TXFIFO_THRESHOLD_1_8) != HAL_OK)
  {
    Error_Handler();
  }
  if (HAL_UARTEx_SetRxFifoThreshold(&hlpuart1, UART_RXFIFO_THRESHOLD_1_8) != HAL_OK)
  {
    Error_Handler();
  }
  if (HAL_UARTEx_DisableFifoMode(&hlpuart1) != HAL_OK)
  {
    Error_Handler();
  }

}

static void MX_SPI1_Init(void)
{

  /* SPI1 parameter configuration*/
  hspi1.Instance = SPI1;
  hspi1.Init.Mode = SPI_MODE_MASTER;
  hspi1.Init.Direction = SPI_DIRECTION_2LINES;
  hspi1.Init.DataSize = SPI_DATASIZE_16BIT;
  hspi1.Init.CLKPolarity = SPI_POLARITY_LOW;
  hspi1.Init.CLKPhase = SPI_PHASE_2EDGE;
  hspi1.Init.NSS = SPI_NSS_SOFT;
  hspi1.Init.BaudRatePrescaler = SPI_BAUDRATEPRESCALER_256;
  hspi1.Init.FirstBit = SPI_FIRSTBIT_MSB;
  hspi1.Init.TIMode = SPI_TIMODE_DISABLE;
  hspi1.Init.CRCCalculation = SPI_CRCCALCULATION_DISABLE;
  hspi1.Init.CRCPolynomial = 7;
  hspi1.Init.CRCLength = SPI_CRC_LENGTH_DATASIZE;
  hspi1.Init.NSSPMode = SPI_NSS_PULSE_DISABLE;
  if (HAL_SPI_Init(&hspi1) != HAL_OK)
  {
    Error_Handler();
  }

}

static void MX_SPI2_Init(void)
{

  /* SPI2 parameter configuration*/
  hspi2.Instance = SPI2;
  hspi2.Init.Mode = SPI_MODE_MASTER;
  hspi2.Init.Direction = SPI_DIRECTION_2LINES;
  hspi2.Init.DataSize = SPI_DATASIZE_16BIT;
  hspi2.Init.CLKPolarity = SPI_POLARITY_LOW;
  hspi2.Init.CLKPhase = SPI_PHASE_2EDGE;
  hspi2.Init.NSS = SPI_NSS_SOFT;
  hspi2.Init.BaudRatePrescaler = SPI_BAUDRATEPRESCALER_32;
  hspi2.Init.FirstBit = SPI_FIRSTBIT_MSB;
  hspi2.Init.TIMode = SPI_TIMODE_DISABLE;
  hspi2.Init.CRCCalculation = SPI_CRCCALCULATION_DISABLE;
  hspi2.Init.CRCPolynomial = 7;
  hspi2.Init.CRCLength = SPI_CRC_LENGTH_DATASIZE;
  hspi2.Init.NSSPMode = SPI_NSS_PULSE_DISABLE;
  if (HAL_SPI_Init(&hspi2) != HAL_OK)
  {
    Error_Handler();
  }

}

static void MX_TIM2_Init(void)
{

  TIM_ClockConfigTypeDef sClockSourceConfig = {0};
  TIM_MasterConfigTypeDef sMasterConfig = {0};

  htim2.Instance = TIM2;
  htim2.Init.Prescaler = 0;
  htim2.Init.CounterMode = TIM_COUNTERMODE_UP;
  htim2.Init.Period = 4294967295;
  htim2.Init.ClockDivision = TIM_CLOCKDIVISION_DIV1;
  htim2.Init.AutoReloadPreload = TIM_AUTORELOAD_PRELOAD_DISABLE;
  if (HAL_TIM_Base_Init(&htim2) != HAL_OK)
  {
    Error_Handler();
  }
  sClockSourceConfig.ClockSource = TIM_CLOCKSOURCE_INTERNAL;
  if (HAL_TIM_ConfigClockSource(&htim2, &sClockSourceConfig) != HAL_OK)
  {
    Error_Handler();
  }
  sMasterConfig.MasterOutputTrigger = TIM_TRGO_RESET;
  sMasterConfig.MasterSlaveMode = TIM_MASTERSLAVEMODE_DISABLE;
  if (HAL_TIMEx_MasterConfigSynchronization(&htim2, &sMasterConfig) != HAL_OK)
  {
    Error_Handler();
  }

}

static void MX_DMA_Init(void)
{

  /* DMA controller clock enable */
  __HAL_RCC_DMAMUX1_CLK_ENABLE();
  __HAL_RCC_DMA1_CLK_ENABLE();

  /* DMA interrupt init */
  /* DMA1_Channel1_IRQn interrupt configuration */
  HAL_NVIC_SetPriority(DMA1_Channel1_IRQn, 6, 0);
  HAL_NVIC_EnableIRQ(DMA1_Channel1_IRQn);
  /* DMA1_Channel2_IRQn interrupt configuration */
  HAL_NVIC_SetPriority(DMA1_Channel2_IRQn, 6, 0);
  HAL_NVIC_EnableIRQ(DMA1_Channel2_IRQn);
  /* DMA1_Channel3_IRQn interrupt configuration */
  HAL_NVIC_SetPriority(DMA1_Channel3_IRQn, 3, 0);
  HAL_NVIC_EnableIRQ(DMA1_Channel3_IRQn);
  /* DMA1_Channel4_IRQn interrupt configuration */
  HAL_NVIC_SetPriority(DMA1_Channel4_IRQn, 3, 0);
  HAL_NVIC_EnableIRQ(DMA1_Channel4_IRQn);
  /* DMA1_Channel5_IRQn interrupt configuration */
  HAL_NVIC_SetPriority(DMA1_Channel5_IRQn, 5, 0);
  HAL_NVIC_EnableIRQ(DMA1_Channel5_IRQn);

}

static void MX_GPIO_Init(void)
{
  GPIO_InitTypeDef GPIO_InitStruct = {0};

  /* GPIO Ports Clock Enable */
  __HAL_RCC_GPIOC_CLK_ENABLE();
  __HAL_RCC_GPIOF_CLK_ENABLE();
  __HAL_RCC_GPIOA_CLK_ENABLE();
  __HAL_RCC_GPIOB_CLK_ENABLE();

  /*Configure GPIO pin Output Level */
  HAL_GPIO_WritePin(GPIOC, GATE_SS_Pin|ENC_SS_Pin, GPIO_PIN_SET);

  /*Configure GPIO pin Output Level */
  HAL_GPIO_WritePin(EXT_SS_GPIO_Port, EXT_SS_Pin, GPIO_PIN_SET);

  /*Configure GPIO pin Output Level */
  HAL_GPIO_WritePin(GPIOC, GATE_EN_Pin|FDCAN_RX_LED_Pin, GPIO_PIN_RESET);

  /*Configure GPIO pin Output Level */
  HAL_GPIO_WritePin(FDCAN_TX_LED_GPIO_Port, FDCAN_TX_LED_Pin, GPIO_PIN_RESET);

  /*Configure GPIO pin Output Level */
  HAL_GPIO_WritePin(FDCAN_STB_GPIO_Port, FDCAN_STB_Pin, GPIO_PIN_RESET);

  /*Configure GPIO pins : LIM_A_Pin LIM_B_Pin */
  GPIO_InitStruct.Pin = LIM_A_Pin|LIM_B_Pin;
  GPIO_InitStruct.Mode = GPIO_MODE_INPUT;
  GPIO_InitStruct.Pull = GPIO_PULLUP;
  HAL_GPIO_Init(GPIOC, &GPIO_InitStruct);

  /*Configure GPIO pins : GATE_SS_Pin GATE_EN_Pin FDCAN_RX_LED_Pin ENC_SS_Pin */
  GPIO_InitStruct.Pin = GATE_SS_Pin|GATE_EN_Pin|FDCAN_RX_LED_Pin|ENC_SS_Pin;
  GPIO_InitStruct.Mode = GPIO_MODE_OUTPUT_PP;
  GPIO_InitStruct.Pull = GPIO_NOPULL;
  GPIO_InitStruct.Speed = GPIO_SPEED_FREQ_LOW;
  HAL_GPIO_Init(GPIOC, &GPIO_InitStruct);

  /*Configure GPIO pins : EXT_SS_Pin FDCAN_TX_LED_Pin */
  GPIO_InitStruct.Pin = EXT_SS_Pin|FDCAN_TX_LED_Pin;
  GPIO_InitStruct.Mode = GPIO_MODE_OUTPUT_PP;
  GPIO_InitStruct.Pull = GPIO_NOPULL;
  GPIO_InitStruct.Speed = GPIO_SPEED_FREQ_LOW;
  HAL_GPIO_Init(GPIOA, &GPIO_InitStruct);

  /*Configure GPIO pins : HALL_B_Pin HALL_C_Pin HALL_A_Pin */
  GPIO_InitStruct.Pin = HALL_B_Pin|HALL_C_Pin|HALL_A_Pin;
  GPIO_InitStruct.Mode = GPIO_MODE_IT_RISING_FALLING;
  GPIO_InitStruct.Pull = GPIO_NOPULL;
  HAL_GPIO_Init(GPIOB, &GPIO_InitStruct);

  /*Configure GPIO pin : FDCAN_STB_Pin */
  GPIO_InitStruct.Pin = FDCAN_STB_Pin;
  GPIO_InitStruct.Mode = GPIO_MODE_OUTPUT_PP;
  GPIO_InitStruct.Pull = GPIO_NOPULL;
  GPIO_InitStruct.Speed = GPIO_SPEED_FREQ_LOW;
  HAL_GPIO_Init(FDCAN_STB_GPIO_Port, &GPIO_InitStruct);

  /* EXTI interrupt init*/
  HAL_NVIC_SetPriority(EXTI9_5_IRQn, 2, 0);
  HAL_NVIC_EnableIRQ(EXTI9_5_IRQn);

  HAL_NVIC_SetPriority(EXTI15_10_IRQn, 2, 0);
  HAL_NVIC_EnableIRQ(EXTI15_10_IRQn);

}

void Error_Handler(void)
{
  __disable_irq();
  while (1)
  {
  }
}
